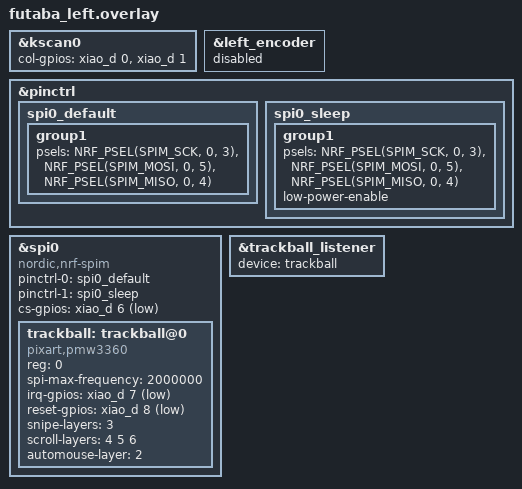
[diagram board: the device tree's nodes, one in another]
#include "futaba.dtsi"

&kscan0 {
col-gpios
= <&xiao_d 0 GPIO_ACTIVE_HIGH>
, <&xiao_d 1 GPIO_ACTIVE_HIGH>
;
};

&left_encoder {
status = "disabled";
};

&pinctrl {
spi0_default: spi0_default {
group1 {
psels = <NRF_PSEL(SPIM_SCK, 0, 3)> // SCLK
, <NRF_PSEL(SPIM_MOSI, 0, 5)> // MOSI
, <NRF_PSEL(SPIM_MISO, 0, 4)> // MISO
;
};
};

spi0_sleep: spi0_sleep {
group1 {
psels = <NRF_PSEL(SPIM_SCK, 0, 3)> // SCLK
, <NRF_PSEL(SPIM_MOSI, 0, 5)> // MOSI
, <NRF_PSEL(SPIM_MISO, 0, 4)> // MISO
;
low-power-enable;
};
};
};

&spi0 {
status = "okay";
compatible = "nordic,nrf-spim";
pinctrl-0 = <&spi0_default>;
pinctrl-1 = <&spi0_sleep>;
pinctrl-names = "default", "sleep";
cs-gpios = <&xiao_d 6 GPIO_ACTIVE_LOW>; //NCS

trackball: trackball@0 {
status = "okay";
compatible = "pixart,pmw3360";
reg = <0>;
spi-max-frequency = <2000000>;
irq-gpios = <&xiao_d 7 (GPIO_ACTIVE_LOW | GPIO_PULL_UP)>; //MOT
reset-gpios = <&xiao_d 8 GPIO_ACTIVE_LOW>; //NRESET (オプション)

snipe-layers = <3>;
scroll-layers = <4 5 6>;
automouse-layer = <2>;
};
};

&trackball_listener {
status = "okay";
device = <&trackball>;
};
